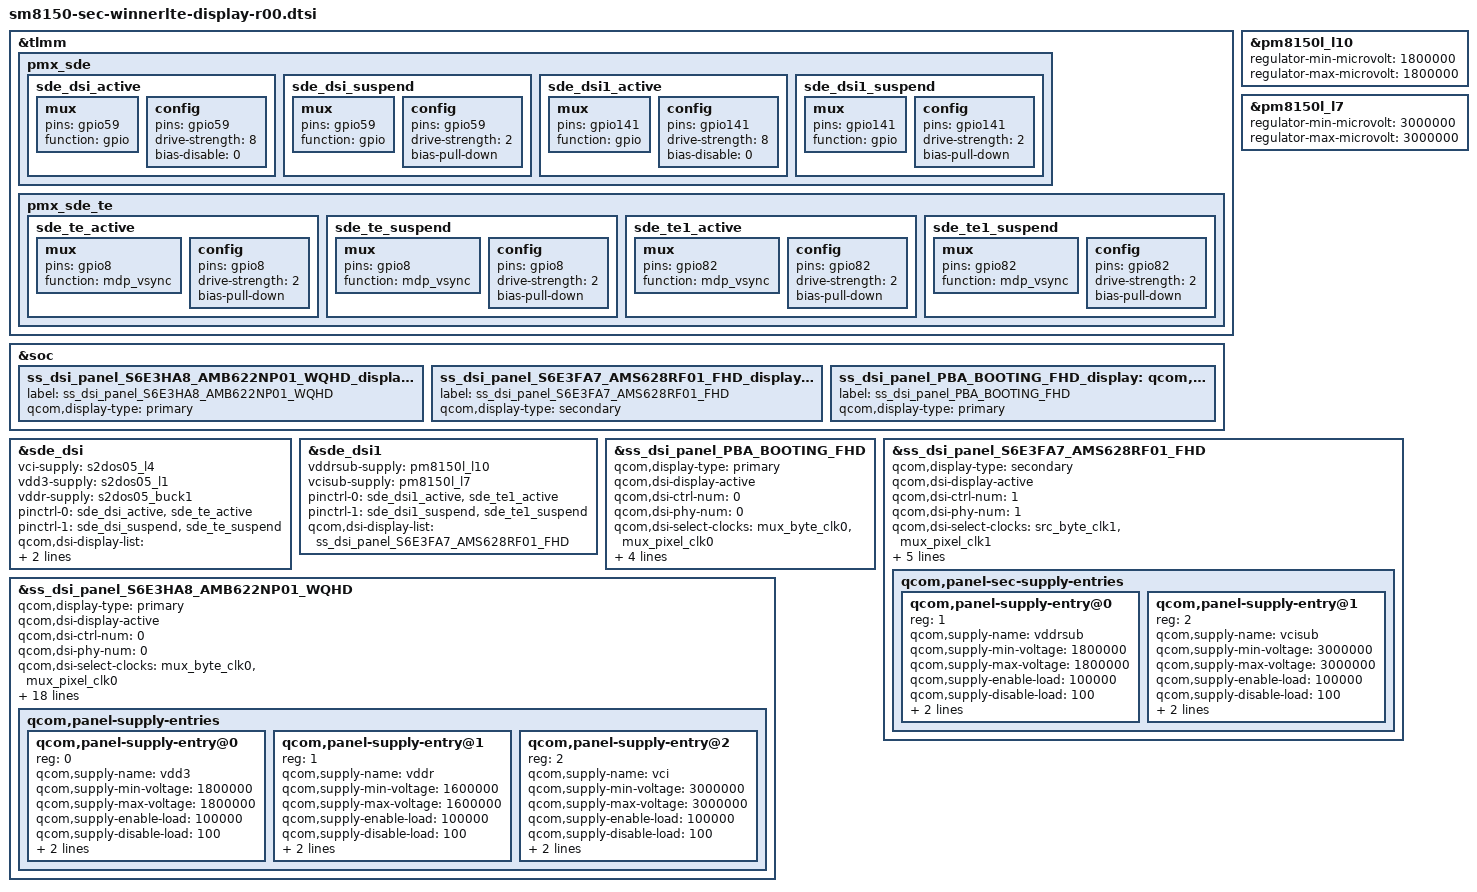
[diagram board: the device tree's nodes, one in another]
/* Copyright (c) 2016-2017, The Linux Foundation. All rights reserved.
 *
 * This program is free software; you can redistribute it and/or modify
 * it under the terms of the GNU General Public License version 2 and
 * only version 2 as published by the Free Software Foundation.
 *
 * This program is distributed in the hope that it will be useful,
 * but WITHOUT ANY WARRANTY; without even the implied warranty of
 * MERCHANTABILITY or FITNESS FOR A PARTICULAR PURPOSE.  See the
 * GNU General Public License for more details.
 */

#include "../../../../../drivers/gpu/drm/msm/samsung/SELF_DISPLAY/self_display_cmd_HA8.dtsi"
#include "../../../../../drivers/gpu/drm/msm/samsung/S6E3HA8_AMB622NP01/dsi_panel_S6E3HA8_AMB622NP01_wqhd_octa_cmd.dtsi"
#include "../../../../../drivers/gpu/drm/msm/samsung/SELF_DISPLAY/self_display_cmd_FA7.dtsi"
#include "../../../../../drivers/gpu/drm/msm/samsung/S6E3FA7_AMS628RF01/dsi_panel_S6E3FA7_AMS628RF01_fhd_octa_cmd.dtsi"
#include "../../../../../drivers/gpu/drm/msm/samsung/PBA_BOOTING/dsi_panel_PBA_BOOTING_fhd_video.dtsi"

&tlmm {
	pmx_sde: pmx_sde {
		sde_dsi_active: sde_dsi_active {
			mux {
				pins = "gpio59";
				function = "gpio";
			};

			config {
				pins = "gpio59";
				drive-strength = <8>;   /* 8 mA */
				bias-disable = <0>;   /* no pull */
			};
		};
		sde_dsi_suspend: sde_dsi_suspend {
			mux {
				pins = "gpio59";
				function = "gpio";
			};

			config {
				pins = "gpio59";
				drive-strength = <2>;   /* 2 mA */
				bias-pull-down;         /* PULL DOWN */
			};
		};

		sde_dsi1_active: sde_dsi1_active {
			mux {
				pins = "gpio141";
				function = "gpio";
			};

			config {
				pins = "gpio141";
				drive-strength = <8>;   /* 8 mA */
				bias-disable = <0>;   /* no pull */
			};
		};
		sde_dsi1_suspend: sde_dsi1_suspend {
			mux {
				pins = "gpio141";
				function = "gpio";
			};

			config {
				pins = "gpio141";
				drive-strength = <2>;   /* 2 mA */
				bias-pull-down;         /* PULL DOWN */
			};
		};
	};
	pmx_sde_te {
		sde_te_active: sde_te_active {
			mux {
				pins = "gpio8";
				function = "mdp_vsync";
			};

			config {
				pins = "gpio8";
				drive-strength = <2>;   /* 2 mA */
				bias-pull-down;         /* PULL DOWN */
			};
		};

		sde_te_suspend: sde_te_suspend {
			mux {
				pins = "gpio8";
				function = "mdp_vsync";
			};

			config {
				pins = "gpio8";
				drive-strength = <2>;   /* 2 mA */
				bias-pull-down;         /* PULL DOWN */
			};
		};

		sde_te1_active: sde_te1_active {
			mux {
				pins = "gpio82";
				function = "mdp_vsync";
			};

			config {
				pins = "gpio82";
				drive-strength = <2>;   /* 2 mA */
				bias-pull-down;         /* PULL DOWN */
			};
		};

		sde_te1_suspend: sde_te1_suspend {
			mux {
				pins = "gpio82";
				function = "mdp_vsync";
			};

			config {
				pins = "gpio82";
				drive-strength = <2>;   /* 2 mA */
				bias-pull-down;         /* PULL DOWN */
			};
		};
	};
};

&soc {
	/* star2 panel */
	ss_dsi_panel_S6E3HA8_AMB622NP01_WQHD_display: qcom,dsi-display@17 {
		label = "ss_dsi_panel_S6E3HA8_AMB622NP01_WQHD";
		qcom,display-type = "primary";
	};

	/* astar panel */
	ss_dsi_panel_S6E3FA7_AMS628RF01_FHD_display: qcom,dsi-display@18 {
		label = "ss_dsi_panel_S6E3FA7_AMS628RF01_FHD";
		qcom,display-type = "secondary";
	};

	/* PBA */
	ss_dsi_panel_PBA_BOOTING_FHD_display: qcom,dsi-display@19 {
		label = "ss_dsi_panel_PBA_BOOTING_FHD";
		qcom,display-type = "primary";
	};
};

/* override display-list / supply for samsung panel */
&sde_dsi {
	vci-supply = <&s2dos05_l4>; /* 3.0V, S2DOS05 LDO4 */
	vdd3-supply = <&s2dos05_l1>; /* 1.8V, S2DOS05 LDO1 */
	vddr-supply = <&s2dos05_buck1>; /* 1.6V, S2DOS05 buck */

	pinctrl-names = "panel_active", "panel_suspend";
	pinctrl-0 = <&sde_dsi_active &sde_te_active>;
	pinctrl-1 = <&sde_dsi_suspend &sde_te_suspend>;

	qcom,dsi-display-list =
		<&ss_dsi_panel_S6E3HA8_AMB622NP01_WQHD
		&ss_dsi_panel_PBA_BOOTING_FHD>;
};

&pm8150l_l10 {	/* vddr, SUB_VDD_DDI_1P8 */
	regulator-min-microvolt = <1800000>;
	regulator-max-microvolt = <1800000>;
};

&pm8150l_l7 {  /* SUB_VDD_DDI_3P0 */
	regulator-min-microvolt = <3000000>;
	regulator-max-microvolt = <3000000>;
};

&sde_dsi1 {
	vddrsub-supply = <&pm8150l_l10>; /* SUB_VDD_DDI_1P8, PM855P VREG_L10 */
	vcisub-supply = <&pm8150l_l7>; /* SUB_VDD_DDI_3P0, PM855P VREG_L7 */

	pinctrl-names = "panel_active", "panel_suspend";
	pinctrl-0 = <&sde_dsi1_active &sde_te1_active>;
	pinctrl-1 = <&sde_dsi1_suspend &sde_te1_suspend>;

	qcom,dsi-display-list =
		<&ss_dsi_panel_S6E3FA7_AMS628RF01_FHD>;
};

&ss_dsi_panel_PBA_BOOTING_FHD {
	qcom,display-type = "primary";
	qcom,dsi-display-active;

	qcom,dsi-ctrl-num = <0>;
	qcom,dsi-phy-num = <0>;
	qcom,dsi-select-clocks = "mux_byte_clk0", "mux_pixel_clk0";

	qcom,dsi-panel = <&ss_dsi_panel_PBA_BOOTING_FHD>;

	qcom,platform-reset-gpio = <&tlmm 59 0>;
	qcom,platform-te-gpio = <&tlmm 8 0>;
	/* In pba booting mode, SS disables continuous splash mode.
	 * But QC recommended to enable splash mode as default..
	 * In case of splash enabled, it should not touch has_src_split  setitng..
	 * Refer to case 03756419.
	 */
	samsung,enable_splash_pba; /* enable continuous spalsh on PBA mode.. */
};

&ss_dsi_panel_S6E3HA8_AMB622NP01_WQHD {
	qcom,display-type = "primary";
	qcom,dsi-display-active;

	qcom,dsi-ctrl-num = <0>;
	qcom,dsi-phy-num = <0>;
	qcom,dsi-select-clocks = "mux_byte_clk0", "mux_pixel_clk0";

	qcom,dsi-panel = <&ss_dsi_panel_S6E3HA8_AMB622NP01_WQHD>;

	qcom,platform-reset-gpio = <&tlmm 59 0>;
	qcom,platform-te-gpio = <&tlmm 8 0>;

	/delete-property/ qcom,panel-mode-gpio;

	qcom,panel-supply-entries {
		#address-cells = <1>;
		#size-cells = <0>;

		qcom,panel-supply-entry@0 {
		    reg = <0>;
		    qcom,supply-name = "vdd3";
		    qcom,supply-min-voltage = <1800000>;
		    qcom,supply-max-voltage = <1800000>;
		    qcom,supply-enable-load = <100000>;
		    qcom,supply-disable-load = <100>;
		    qcom,supply-pre-on-sleep = <0>; /* unit is ms*/
		    qcom,supply-post-on-sleep = <0>;
		};

		qcom,panel-supply-entry@1 {
		    reg = <1>;
		    qcom,supply-name = "vddr";
		    qcom,supply-min-voltage = <1600000>;
		    qcom,supply-max-voltage = <1600000>;
		    qcom,supply-enable-load = <100000>;
		    qcom,supply-disable-load = <100>;
		    qcom,supply-pre-on-sleep = <0>; /* unit is ms*/
		    qcom,supply-post-on-sleep = <0>;
		};

		qcom,panel-supply-entry@2 {
		    reg = <2>;
		    qcom,supply-name = "vci";
		    qcom,supply-min-voltage = <3000000>;
		    qcom,supply-max-voltage = <3000000>;
		    qcom,supply-enable-load = <100000>;
		    qcom,supply-disable-load = <100>;
		    qcom,supply-pre-on-sleep = <0>; /* unit is ms*/
		    qcom,supply-post-on-sleep = <0>;
		};
	};
};

&ss_dsi_panel_S6E3HA8_AMB622NP01_WQHD {
	samsung,esd-irq-gpio1 = <&pm8150_gpios 1 0>; // DISP_DET
	samsung,delayed-display-on = <1>;

	samsung,lpm-power-control;
	samsung,lpm-power-control-supply-name = "vddr";
	samsung,lpm-power-control-supply-min-voltage = <1500000>;
	samsung,lpm-power-control-supply-max-voltage = <1500000>;
	samsung,lpm-power-control-elvss-name = "s2dos05-elvss";
	samsung,lpm-power-control-elvss-lpm-voltage = <2000>;
	samsung,lpm-power-control-elvss-normal-voltage = <8000>;
};


&ss_dsi_panel_S6E3FA7_AMS628RF01_FHD{
	qcom,display-type = "secondary";
	qcom,dsi-display-active;

	qcom,dsi-ctrl-num = <1>;
	qcom,dsi-phy-num = <1>;
	qcom,dsi-select-clocks = "src_byte_clk1", "mux_pixel_clk1";

	qcom,dsi-panel = <&ss_dsi_panel_S6E3FA7_AMS628RF01_FHD>;

	qcom,platform-sec-reset-gpio = <&tlmm 141 0>;
	qcom,platform-te-gpio = <&tlmm 81 0>;
	samsung,esd-irq-gpio1 = <&tlmm 93 0>; // SUB_DISP_DET

	/delete-property/ qcom,panel-mode-gpio;

	qcom,panel-sec-supply-entries {
		#address-cells = <1>;
		#size-cells = <0>;

		qcom,panel-supply-entry@0 {
		    reg = <1>;
		    qcom,supply-name = "vddrsub";
		    qcom,supply-min-voltage = <1800000>;
		    qcom,supply-max-voltage = <1800000>;
		    qcom,supply-enable-load = <100000>;
		    qcom,supply-disable-load = <100>;
		    qcom,supply-pre-on-sleep = <0>; /* unit is ms*/
		    qcom,supply-post-on-sleep = <0>;
		};

		qcom,panel-supply-entry@1 {
		    reg = <2>;
		    qcom,supply-name = "vcisub";
		    qcom,supply-min-voltage = <3000000>;
		    qcom,supply-max-voltage = <3000000>;
		    qcom,supply-enable-load = <100000>;
		    qcom,supply-disable-load = <100>;
		    qcom,supply-pre-on-sleep = <0>; /* unit is ms*/
		    qcom,supply-post-on-sleep = <10>;
		};
	};
};
